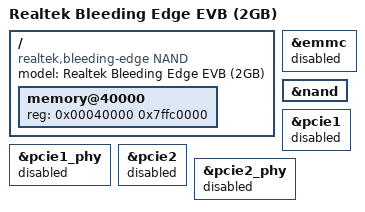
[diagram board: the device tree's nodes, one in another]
// SPDX-License-Identifier: (GPL-2.0-or-later OR BSD-2-Clause)
/*
 * Copyright (c) 2020 Realtek Semiconductor Corp.
 */

/dts-v1/;

#include "rtd1619b-bleedingedge.dtsi"

/ {
	compatible = "realtek,bleeding-edge NAND", "realtek,rtd1619b";
	model = "Realtek Bleeding Edge EVB (2GB)";

	memory@40000 {
		device_type = "memory";
		reg = <0x00040000 0x7ffc0000>; /* 2 GB */
	};
};

&emmc {
	status = "disabled";
};

&nand {
	status = "okay";
};

&pcie1 {
	status = "disabled";
};

&pcie1_phy {
	status = "disabled";
};

&pcie2 {
	status = "disabled";
};

&pcie2_phy {
	status = "disabled";
};
